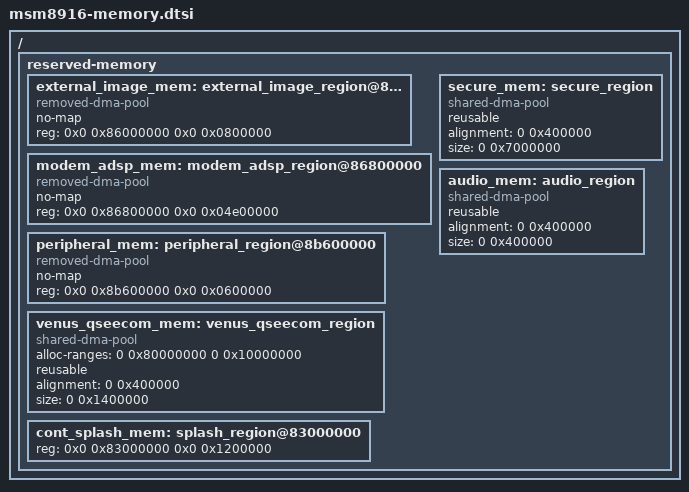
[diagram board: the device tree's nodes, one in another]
/* Copyright (c) 2014, The Linux Foundation. All rights reserved.
 *
 * This program is free software; you can redistribute it and/or modify
 * it under the terms of the GNU General Public License version 2 and
 * only version 2 as published by the Free Software Foundation.
 *
 * This program is distributed in the hope that it will be useful,
 * but WITHOUT ANY WARRANTY; without even the implied warranty of
 * MERCHANTABILITY or FITNESS FOR A PARTICULAR PURPOSE.  See the
 * GNU General Public License for more details.
 */

#include "msm8916-ion.dtsi"

/ {
	reserved-memory {
		#address-cells = <2>;
		#size-cells = <2>;
		ranges;

		external_image_mem: external_image_region@86000000 {
			compatible = "removed-dma-pool";
			no-map;
			reg = <0x0 0x86000000 0x0 0x0800000>;
		};

		modem_adsp_mem: modem_adsp_region@86800000 {
			compatible = "removed-dma-pool";
			no-map;
			reg = <0x0 0x86800000 0x0 0x04e00000>;
		};

		peripheral_mem: peripheral_region@8b600000 {
			compatible = "removed-dma-pool";
			no-map;
			reg = <0x0 0x8b600000 0x0 0x0600000>;
		};

		secure_mem: secure_region {
                        compatible = "shared-dma-pool";
                        reusable;
			alignment = <0 0x400000>;
			size = <0 0x7000000>;
		};

		venus_qseecom_mem: venus_qseecom_region {
                        compatible = "shared-dma-pool";
			alloc-ranges = <0 0x80000000 0 0x10000000>;
                        reusable;
			alignment = <0 0x400000>;
			size = <0 0x1400000>;
		};

		audio_mem: audio_region {
                        compatible = "shared-dma-pool";
                        reusable;
			alignment = <0 0x400000>;
			size = <0 0x400000>;
		};

		cont_splash_mem: splash_region@83000000 {
			reg = <0x0 0x83000000 0x0 0x1200000>;
		};
	};
};
